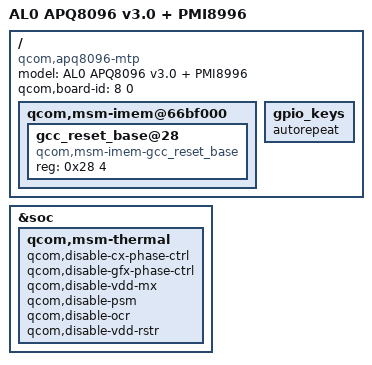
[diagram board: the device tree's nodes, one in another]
/* 2017-10-12: File added and changed by Sony Corporation */
/*
 * dts for AL0 APQ8096 v3.0 + PMI8996
 *
 * Copyright 2017 Sony Corporation
 *
 * Original code is msm8996-v3.0-pmi8996-mtp.dts
 */
/* Copyright (c) 2015, The Linux Foundation. All rights reserved.
 *
 * This program is free software; you can redistribute it and/or modify
 * it under the terms of the GNU General Public License version 2 and
 * only version 2 as published by the Free Software Foundation.
 *
 * This program is distributed in the hope that it will be useful,
 * but WITHOUT ANY WARRANTY; without even the implied warranty of
 * MERCHANTABILITY or FITNESS FOR A PARTICULAR PURPOSE.  See the
 * GNU General Public License for more details.
 */


/dts-v1/;

#include "apq8096-v3.0.dtsi"
#include "msm-pmi8996.dtsi"
#include "al-common.dtsi"

/ {
	model = "AL0 APQ8096 v3.0 + PMI8996";
	compatible = "qcom,apq8096-mtp","qcom,apq8096","qcom,mtp";
	qcom,board-id = <8 0>;

	qcom,msm-imem@66bf000 {
		#address-cells = <1>;
		#size-cells = <0>;

		gcc_reset_base@28 {
			compatible = "qcom,msm-imem-gcc_reset_base";
			reg = <0x28 4>;
		};
	};

	gpio_keys {
		autorepeat;
	};
};

&soc {
	qcom,msm-thermal {
		qcom,disable-cx-phase-ctrl;
		qcom,disable-gfx-phase-ctrl;
		qcom,disable-vdd-mx;
		qcom,disable-psm;
		qcom,disable-ocr;
		qcom,disable-vdd-rstr;
	};
};
